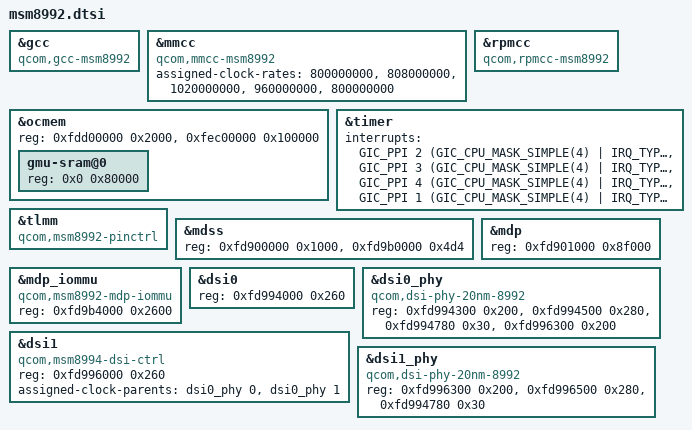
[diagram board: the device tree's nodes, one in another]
// SPDX-License-Identifier: GPL-2.0-only
/*
 * Copyright (c) 2013-2016, The Linux Foundation. All rights reserved.
 */

#include "msm8994.dtsi"

/* 8992 only features 2 A57 cores. */
/delete-node/ &cpu6;
/delete-node/ &cpu7;
/delete-node/ &cpu6_map;
/delete-node/ &cpu7_map;

&gcc {
	compatible = "qcom,gcc-msm8992";
};

&mmcc {
	compatible = "qcom,mmcc-msm8992";

	assigned-clock-rates = <800000000>,
			       <808000000>,
			       <1020000000>,
			       <960000000>,
			       <800000000>;
};

&ocmem {
	reg = <0xfdd00000 0x2000>, <0xfec00000 0x100000>;

	gmu-sram@0 {
		reg = <0x0 0x80000>;
	};
};

&rpmcc {
	compatible = "qcom,rpmcc-msm8992", "qcom,rpmcc";
};

&timer {
	interrupts = <GIC_PPI 2 (GIC_CPU_MASK_SIMPLE(4) | IRQ_TYPE_LEVEL_LOW)>,
			     <GIC_PPI 3 (GIC_CPU_MASK_SIMPLE(4) | IRQ_TYPE_LEVEL_LOW)>,
			     <GIC_PPI 4 (GIC_CPU_MASK_SIMPLE(4) | IRQ_TYPE_LEVEL_LOW)>,
			     <GIC_PPI 1 (GIC_CPU_MASK_SIMPLE(4) | IRQ_TYPE_LEVEL_LOW)>;
};

&tlmm {
	compatible = "qcom,msm8992-pinctrl";
};

&mdss {
	reg = <0xfd900000 0x1000>,
	      <0xfd9b0000 0x4d4>;
};

&mdp {
	reg = <0xfd901000 0x8f000>;
};

&mdp_iommu {
	compatible = "qcom,msm8992-mdp-iommu";
	reg = <0xfd9b4000 0x2600>;
	ranges = <0 0xfd9bc000 0x3000>;
};

&dsi0 {
	reg = <0xfd994000 0x260>;
};

&dsi0_phy {
	compatible = "qcom,dsi-phy-20nm-8992";
	reg = <0xfd994300 0x200>,
	      <0xfd994500 0x280>,
	      <0xfd994780 0x30>,
	      <0xfd996300 0x200>;
	reg-names = "dsi_pll", "dsi_phy", "dsi_phy_regulator", "dsi_pll_1";
};

&dsi1 {
	compatible = "qcom,msm8994-dsi-ctrl", "qcom,mdss-dsi-ctrl";
	reg = <0xfd996000 0x260>;
	assigned-clock-parents = <&dsi0_phy 0>, <&dsi0_phy 1>;
};

&dsi1_phy {
	compatible = "qcom,dsi-phy-20nm-8992";
	reg = <0xfd996300 0x200>,
	      <0xfd996500 0x280>,
	      <0xfd994780 0x30>;
	reg-names = "dsi_pll", "dsi_phy", "dsi_phy_regulator";
};
